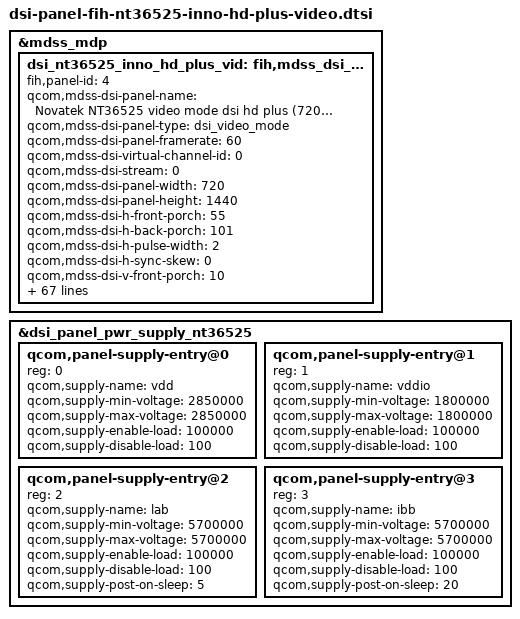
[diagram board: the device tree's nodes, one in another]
/* Copyright (c) 2018, The Linux Foundation. All rights reserved.
 *
 * This program is free software; you can redistribute it and/or modify
 * it under the terms of the GNU General Public License version 2 and
 * only version 2 as published by the Free Software Foundation.
 *
 * This program is distributed in the hope that it will be useful,
 * but WITHOUT ANY WARRANTY; without even the implied warranty of
 * MERCHANTABILITY or FITNESS FOR A PARTICULAR PURPOSE.  See the
 * GNU General Public License for more details.
 */

&mdss_mdp {
	dsi_nt36525_inno_hd_plus_vid: fih,mdss_dsi_nt36525_inno_hd_plus_video{
		fih,panel-id = <4>;
		qcom,mdss-dsi-panel-name = "Novatek NT36525 video mode dsi hd plus (720x1440) inno panel";
		qcom,mdss-dsi-panel-type = "dsi_video_mode";
		qcom,mdss-dsi-panel-framerate = <60>;
		qcom,mdss-dsi-virtual-channel-id = <0>;
		qcom,mdss-dsi-stream = <0>;
		qcom,mdss-dsi-panel-width = <720>;
		qcom,mdss-dsi-panel-height = <1440>;

		qcom,mdss-dsi-h-front-porch = <55>;
		qcom,mdss-dsi-h-back-porch = <101>;
		qcom,mdss-dsi-h-pulse-width = <2>;
		qcom,mdss-dsi-h-sync-skew = <0>;
		qcom,mdss-dsi-v-front-porch = <10>;
		qcom,mdss-dsi-v-back-porch = <8>;
		qcom,mdss-dsi-v-pulse-width = <2>;

		qcom,mdss-dsi-h-left-border = <0>;
		qcom,mdss-dsi-h-right-border = <0>;
		qcom,mdss-dsi-v-top-border = <0>;
		qcom,mdss-dsi-v-bottom-border = <0>;
		qcom,mdss-dsi-bpp = <24>;
		qcom,mdss-dsi-color-order = "rgb_swap_rgb";
		qcom,mdss-dsi-underflow-color = <0xff>;
		qcom,mdss-dsi-border-color = <0>;
		qcom,mdss-dsi-on-command = [
                    39 01 00 00 0A 00 02 FF 20
                    39 01 00 00 00 00 02 FB 01
                    39 01 00 00 00 00 02 01 55
                    39 01 00 00 00 00 02 03 55
                    39 01 00 00 00 00 02 05 B1
                    39 01 00 00 00 00 02 07 73
                    39 01 00 00 00 00 02 08 CB
                    39 01 00 00 00 00 02 0E 91
                    39 01 00 00 00 00 02 0F 69
                    39 01 00 00 00 00 02 69 A9
                    39 01 00 00 00 00 02 94 00
                    39 01 00 00 00 00 02 95 FF
                    39 01 00 00 00 00 02 96 FF
                    39 01 00 00 0A 00 02 FF 24
                    39 01 00 00 00 00 02 FB 01
                    39 01 00 00 00 00 02 93 0A
                    39 01 00 00 00 00 02 94 0A
                    39 01 00 00 00 00 02 00 04
                    39 01 00 00 00 00 02 01 05
                    39 01 00 00 00 00 02 02 00
                    39 01 00 00 00 00 02 03 00
                    39 01 00 00 00 00 02 04 08
                    39 01 00 00 00 00 02 05 18
                    39 01 00 00 00 00 02 06 19
                    39 01 00 00 00 00 02 07 0C
                    39 01 00 00 00 00 02 08 0D
                    39 01 00 00 00 00 02 09 0E
                    39 01 00 00 00 00 02 0A 0F
                    39 01 00 00 00 00 02 0B 10
                    39 01 00 00 00 00 02 0C 11
                    39 01 00 00 00 00 02 16 04
                    39 01 00 00 00 00 02 17 05
                    39 01 00 00 00 00 02 18 00
                    39 01 00 00 00 00 02 19 00
                    39 01 00 00 00 00 02 1A 08
                    39 01 00 00 00 00 02 1B 18
                    39 01 00 00 00 00 02 1C 19
                    39 01 00 00 00 00 02 1D 0C
                    39 01 00 00 00 00 02 1E 0D
                    39 01 00 00 00 00 02 1F 0E
                    39 01 00 00 00 00 02 20 0F
                    39 01 00 00 00 00 02 21 10
                    39 01 00 00 00 00 02 22 11
                    39 01 00 00 00 00 02 2F 04
                    39 01 00 00 00 00 02 30 32
                    39 01 00 00 00 00 02 33 32
                    39 01 00 00 00 00 02 34 04
                    39 01 00 00 00 00 02 37 44
                    39 01 00 00 00 00 02 39 00
                    39 01 00 00 00 00 02 3A 10
                    39 01 00 00 00 00 02 3B A3
                    39 01 00 00 00 00 02 3D 52
                    39 01 00 00 00 00 02 3F 41
                    39 01 00 00 00 00 02 40 00
                    39 01 00 00 00 00 02 43 41
                    39 01 00 00 00 00 02 44 06
                    39 01 00 00 00 00 02 47 44
                    39 01 00 00 00 00 02 49 00
                    39 01 00 00 00 00 02 4A 10
                    39 01 00 00 00 00 02 4B A3
                    39 01 00 00 00 00 02 4C 51
                    39 01 00 00 00 00 02 4D 12
                    39 01 00 00 00 00 02 4E 34
                    39 01 00 00 00 00 02 4F 56
                    39 01 00 00 00 00 02 51 65
                    39 01 00 00 00 00 02 52 43
                    39 01 00 00 00 00 02 53 21
                    39 01 00 00 00 00 02 55 43
                    39 01 00 00 00 00 02 56 46
                    39 01 00 00 00 00 02 5A 10
                    39 01 00 00 00 00 02 5B A3
                    39 01 00 00 00 00 02 5E 06
                    39 01 00 00 00 00 02 5F 00
                    39 01 00 00 00 00 02 92 C0
                    39 01 00 00 00 00 02 76 00
                    39 01 00 00 00 00 02 77 00
                    39 01 00 00 00 00 02 78 00
                    39 01 00 00 00 00 02 79 00
                    39 01 00 00 00 00 02 7A 20
                    39 01 00 00 00 00 02 7B 3C
                    39 01 00 00 00 00 02 7C 00
                    39 01 00 00 00 00 02 7D 00
                    39 01 00 00 00 00 02 7E 08
                    39 01 00 00 00 00 02 87 02
                    39 01 00 00 00 00 02 AB 00
                    39 01 00 00 00 00 02 AC 00
                    39 01 00 00 00 00 02 AD 00
                    39 01 00 00 00 00 02 AF 04
                    39 01 00 00 00 00 02 B0 05
                    39 01 00 00 00 00 02 B1 BB
                    39 01 00 00 00 00 02 60 80
                    39 01 00 00 00 00 02 61 68
                    39 01 00 00 00 00 02 64 11
                    39 01 00 00 0A 00 02 FF 25
                    39 01 00 00 00 00 02 FB 01
                    39 01 00 00 00 00 02 0A 82
                    39 01 00 00 00 00 02 0B BE
                    39 01 00 00 00 00 02 0C 01
                    39 01 00 00 00 00 02 17 82
                    39 01 00 00 00 00 02 18 06
                    39 01 00 00 00 00 02 19 0F
                    39 01 00 00 00 00 02 1E 00
                    39 01 00 00 00 00 02 1F 10
                    39 01 00 00 00 00 02 20 A3
                    39 01 00 00 00 00 02 23 05
                    39 01 00 00 00 00 02 24 BB
                    39 01 00 00 00 00 02 25 00
                    39 01 00 00 00 00 02 26 10
                    39 01 00 00 00 00 02 27 A3
                    39 01 00 00 00 00 02 2A 05
                    39 01 00 00 00 00 02 2B BB
                    39 01 00 00 00 00 02 2D 80
                    39 01 00 00 00 00 02 2F 50
                    39 01 00 00 00 00 02 30 10
                    39 01 00 00 00 00 02 31 00
                    39 01 00 00 00 00 02 32 00
                    39 01 00 00 00 00 02 33 10
                    39 01 00 00 00 00 02 34 A3
                    39 01 00 00 00 00 02 37 05
                    39 01 00 00 00 00 02 38 BB
                    39 01 00 00 00 00 02 40 10
                    39 01 00 00 00 00 02 41 80
                    39 01 00 00 00 00 02 42 10
                    39 01 00 00 00 00 02 43 A3
                    39 01 00 00 00 00 02 46 05
                    39 01 00 00 00 00 02 47 BB
                    39 01 00 00 00 00 02 4A 00
                    39 01 00 00 00 00 02 4B 10
                    39 01 00 00 00 00 02 4C A3
                    39 01 00 00 00 00 02 4D 10
                    39 01 00 00 00 00 02 4E A3
                    39 01 00 00 00 00 02 4F 10
                    39 01 00 00 00 00 02 50 A3
                    39 01 00 00 00 00 02 53 05
                    39 01 00 00 00 00 02 54 BB
                    39 01 00 00 00 00 02 55 05
                    39 01 00 00 00 00 02 56 BB
                    39 01 00 00 00 00 02 58 00
                    39 01 00 00 00 00 02 59 00
                    39 01 00 00 00 00 02 5A 60
                    39 01 00 00 00 00 02 5B 80
                    39 01 00 00 00 00 02 5C 00
                    39 01 00 00 00 00 02 5D 10
                    39 01 00 00 00 00 02 5E A3
                    39 01 00 00 00 00 02 5F 10
                    39 01 00 00 00 00 02 60 A3
                    39 01 00 00 00 00 02 61 10
                    39 01 00 00 00 00 02 62 A3
                    39 01 00 00 00 00 02 65 05
                    39 01 00 00 00 00 02 66 BB
                    39 01 00 00 00 00 02 6B 07
                    39 01 00 00 00 00 02 6C 4A
                    39 01 00 00 00 00 02 6D 94
                    39 01 00 00 00 00 02 6E 0D
                    39 01 00 00 00 00 02 6F 17
                    39 01 00 00 00 00 02 70 54
                    39 01 00 00 00 00 02 71 8A
                    39 01 00 00 00 00 02 72 17
                    39 01 00 00 00 00 02 73 0D
                    39 01 00 00 00 00 02 78 00
                    39 01 00 00 00 00 02 79 05
                    39 01 00 00 00 00 02 7A 00
                    39 01 00 00 00 00 02 7B B0
                    39 01 00 00 00 00 02 7C 00
                    39 01 00 00 00 00 02 7D 05
                    39 01 00 00 00 00 02 7E 00
                    39 01 00 00 00 00 02 7F B0
                    39 01 00 00 0A 00 02 FF 26
                    39 01 00 00 00 00 02 FB 01
                    39 01 00 00 00 00 02 04 4B
                    39 01 00 00 00 00 02 06 01
                    39 01 00 00 00 00 02 0C 0B
                    39 01 00 00 00 00 02 0D 01
                    39 01 00 00 00 00 02 0E 02
                    39 01 00 00 00 00 02 0F 06
                    39 01 00 00 00 00 02 10 07
                    39 01 00 00 00 00 02 12 00
                    39 01 00 00 00 00 02 13 28
                    39 01 00 00 00 00 02 14 80
                    39 01 00 00 00 00 02 16 81
                    39 01 00 00 00 00 02 19 15
                    39 01 00 00 00 00 02 1A 6A
                    39 01 00 00 00 00 02 1B 0D
                    39 01 00 00 00 00 02 1C D2
                    39 01 00 00 00 00 02 1D 00
                    39 01 00 00 00 00 02 1E C0
                    39 01 00 00 00 00 02 1F C0
                    39 01 00 00 00 00 02 24 01
                    39 01 00 00 00 00 02 25 C0
                    39 01 00 00 00 00 02 26 66
                    39 01 00 00 00 00 02 27 66
                    39 01 00 00 00 00 02 28 66
                    39 01 00 00 00 00 02 29 06
                    39 01 00 00 00 00 02 2F 00
                    39 01 00 00 00 00 02 30 C0
                    39 01 00 00 00 00 02 31 11
                    39 01 00 00 00 00 02 32 11
                    39 01 00 00 00 00 02 34 05
                    39 01 00 00 00 00 02 35 C0
                    39 01 00 00 00 00 02 36 11
                    39 01 00 00 00 00 02 37 78
                    39 01 00 00 00 00 02 38 66
                    39 01 00 00 00 00 02 39 06
                    39 01 00 00 00 00 02 3F 06
                    39 01 00 00 00 00 02 40 C0
                    39 01 00 00 00 00 02 41 66
                    39 01 00 00 00 00 02 42 66
                    39 01 00 00 00 00 02 43 06
                    39 01 00 00 00 00 02 58 E1
                    39 01 00 00 00 00 02 59 E1
                    39 01 00 00 00 00 02 5A E1
                    39 01 00 00 00 00 02 5B E1
                    39 01 00 00 00 00 02 5C 00
                    39 01 00 00 00 00 02 5D 00
                    39 01 00 00 00 00 02 5E 06
                    39 01 00 00 00 00 02 5F 66
                    39 01 00 00 00 00 02 60 66
                    39 01 00 00 00 00 02 61 06
                    39 01 00 00 00 00 02 63 10
                    39 01 00 00 00 00 02 64 A3
                    39 01 00 00 00 00 02 65 10
                    39 01 00 00 00 00 02 66 A3
                    39 01 00 00 00 00 02 67 10
                    39 01 00 00 00 00 02 68 A3
                    39 01 00 00 00 00 02 6B 00
                    39 01 00 00 00 00 02 6C 00
                    39 01 00 00 00 00 02 6D 00
                    39 01 00 00 00 00 02 6F 04
                    39 01 00 00 00 00 02 70 05
                    39 01 00 00 00 00 02 71 DC
                    39 01 00 00 00 00 02 73 10
                    39 01 00 00 00 00 02 74 A3
                    39 01 00 00 00 00 02 77 05
                    39 01 00 00 00 00 02 78 DC
                    39 01 00 00 00 00 02 7A 10
                    39 01 00 00 00 00 02 7B A3
                    39 01 00 00 00 00 02 7E 05
                    39 01 00 00 00 00 02 7F DC
                    39 01 00 00 00 00 02 82 10
                    39 01 00 00 00 00 02 83 A3
                    39 01 00 00 00 00 02 84 10
                    39 01 00 00 00 00 02 85 A3
                    39 01 00 00 00 00 02 86 10
                    39 01 00 00 00 00 02 87 A3
                    39 01 00 00 00 00 02 8A 05
                    39 01 00 00 00 00 02 8B DC
                    39 01 00 00 00 00 02 8C 00
                    39 01 00 00 00 00 02 8D 00
                    39 01 00 00 00 00 02 8E 01
                    39 01 00 00 00 00 02 8F 00
                    39 01 00 00 00 00 02 90 00
                    39 01 00 00 00 00 02 91 00
                    39 01 00 00 00 00 02 92 05
                    39 01 00 00 00 00 02 93 A0
                    39 01 00 00 00 00 02 94 00
                    39 01 00 00 00 00 02 95 00
                    39 01 00 00 00 00 02 96 00
                    39 01 00 00 00 00 02 99 18
                    39 01 00 00 00 00 02 9A 06
                    39 01 00 00 00 00 02 9B 17
                    39 01 00 00 00 00 02 9C 6E
                    39 01 00 00 0A 00 02 FF 27
                    39 01 00 00 00 00 02 FB 01
                    39 01 00 00 00 00 02 96 03
                    39 01 00 00 00 00 02 97 15
                    39 01 00 00 00 00 02 98 11
                    39 01 00 00 00 00 02 99 3F
                    39 01 00 00 00 00 02 9B 3F
                    39 01 00 00 00 00 02 9D 25
                    39 01 00 00 00 00 02 9E 55
                    39 01 00 00 00 00 02 9F 05
                    39 01 00 00 00 00 02 AD 25
                    39 01 00 00 00 00 02 AE 55
                    39 01 00 00 00 00 02 AF 05
                    39 01 00 00 00 00 02 B3 C6
                    39 01 00 00 0A 00 02 FF 23
                    39 01 00 00 00 00 02 FB 01
                    39 01 00 00 00 00 02 12 A2
                    39 01 00 00 00 00 02 15 81
                    39 01 00 00 00 00 02 16 0A
			39 01 00 00 0A 00 02 FF 20 
			39 01 00 00 00 00 02 FB 01 
			39 01 00 00 00 00 11 B0 00 00 00 0D 00 26 00 3B 00 4E 00 5F 00 6E 00 7C 
			39 01 00 00 00 00 11 B1 00 8A 00 B7 00 DC 01 16 01 44 01 8D 01 C9 01 CA 
			39 01 00 00 00 00 11 B2 02 01 02 42 02 6C 02 A5 02 CC 02 F8 03 04 03 11 
			39 01 00 00 00 00 0D B3 03 27 03 36 03 44 03 50 03 57 03 DB 
			39 01 00 00 00 00 11 B4 00 00 00 0D 00 26 00 3B 00 4E 00 5F 00 6E 00 7C 
			39 01 00 00 00 00 11 B5 00 8A 00 B7 00 DC 01 16 01 44 01 8D 01 C9 01 CA 
			39 01 00 00 00 00 11 B6 02 01 02 42 02 6C 02 A5 02 CC 02 F8 03 04 03 11 
			39 01 00 00 00 00 0D B7 03 27 03 36 03 44 03 50 03 57 03 DB 
			39 01 00 00 00 00 11 B8 00 00 00 0D 00 26 00 3B 00 4E 00 5F 00 6E 00 7C 
			39 01 00 00 00 00 11 B9 00 8A 00 B7 00 DC 01 16 01 44 01 8D 01 C9 01 CA 
			39 01 00 00 00 00 11 BA 02 01 02 42 02 6C 02 A5 02 CC 02 F8 03 04 03 11 
			39 01 00 00 00 00 0D BB 03 27 03 36 03 44 03 50 03 57 03 DB 
			39 01 00 00 0A 00 02 FF 21 
			39 01 00 00 00 00 02 FB 01 
			39 01 00 00 00 00 11 B0 00 00 00 0D 00 26 00 3B 00 4E 00 5F 00 6E 00 7C 
			39 01 00 00 00 00 11 B1 00 8A 00 B7 00 DC 01 16 01 44 01 8D 01 C9 01 CA 
			39 01 00 00 00 00 11 B2 02 01 02 42 02 6C 02 A5 02 CC 02 F8 03 04 03 11 
			39 01 00 00 00 00 0D B3 03 27 03 36 03 44 03 50 03 57 03 DB 
			39 01 00 00 00 00 11 B4 00 00 00 0D 00 26 00 3B 00 4E 00 5F 00 6E 00 7C 
			39 01 00 00 00 00 11 B5 00 8A 00 B7 00 DC 01 16 01 44 01 8D 01 C9 01 CA 
			39 01 00 00 00 00 11 B6 02 01 02 42 02 6C 02 A5 02 CC 02 F8 03 04 03 11 
			39 01 00 00 00 00 0D B7 03 27 03 36 03 44 03 50 03 57 03 DB 
			39 01 00 00 00 00 11 B8 00 00 00 0D 00 26 00 3B 00 4E 00 5F 00 6E 00 7C 
			39 01 00 00 00 00 11 B9 00 8A 00 B7 00 DC 01 16 01 44 01 8D 01 C9 01 CA 
			39 01 00 00 00 00 11 BA 02 01 02 42 02 6C 02 A5 02 CC 02 F8 03 04 03 11 
			39 01 00 00 00 00 0D BB 03 27 03 36 03 44 03 50 03 57 03 DB 
                    39 01 00 00 0A 00 02 FF 10
                    39 01 00 00 00 00 02 FB 01
                    05 01 00 00 00 00 02 29 00
                    05 01 00 00 78 00 02 11 00
		];
		qcom,mdss-dsi-off-command = [
				05 00 00 00 00 00 02 28 00
				05 01 00 00 96 00 02 10 00
		];
		qcom,mdss-dsi-on-command-state = "dsi_lp_mode";
		qcom,mdss-dsi-off-command-state = "dsi_lp_mode";
		qcom,mdss-dsi-h-sync-pulse = <0>;
		qcom,mdss-dsi-traffic-mode = "non_burst_sync_event";
		qcom,mdss-dsi-lane-map = "lane_map_0123";
		qcom,mdss-dsi-bllp-eof-power-mode;
		qcom,mdss-dsi-bllp-power-mode;
		qcom,mdss-dsi-tx-eot-append;
		qcom,mdss-dsi-lane-0-state;
		qcom,mdss-dsi-lane-1-state;
		qcom,mdss-dsi-lane-2-state;
		qcom,mdss-dsi-lane-3-state;
		qcom,mdss-dsi-t-clk-post = <0x04>;
		qcom,mdss-dsi-t-clk-pre = <0x1B>;
		qcom,mdss-dsi-dma-trigger = "trigger_sw";
		qcom,mdss-dsi-mdp-trigger = "none";
		qcom,mdss-dsi-reset-sequence = <1 20>;

		qcom,mdss-pan-physical-width-dimension = <68>;
		qcom,mdss-pan-physical-height-dimension = <136>;
		qcom,mdss-pan-physical-width-dimension-full = <6804>;
		qcom,mdss-pan-physical-height-dimension-full = <13608>;

		/* ******************** */
		/* START of Dynamic Read Write Register */
		/* ******************** */
		/* SW4-HL-Display-DynamicReadWriteRegister-00+{_20160729 */
		fih,mdss-dsi-write-reg-command = [
			39 01 00 00 00 00 04 FF 78 07 00
		];

		fih,mdss-dsi-write-reg-command-state = "dsi_lp_mode";
		/* SW4-HL-Display-DynamicReadWriteRegister-00+}_20160729 */
		/* ******************** */
		/* START of Dynamic Read Write Register */
		/* ******************** */
	};
};

&dsi_nt36525_inno_hd_plus_vid {
	/delete-property/ qcom,mdss-dsi-panel-timings;
	qcom,mdss-dsi-panel-timings = [
		88 1C 12 00 42 44 18 20 16 03 04 00
	];

	qcom,mdss-dsi-panel-timings-phy-v2 = [
		1E 1C 04 06 02 03 04 a0
		1E 1C 04 06 02 03 04 a0
		1E 1C 04 06 02 03 04 a0
		1E 1C 04 06 02 03 04 a0
		1E 1C 04 06 02 03 04 a0
	];

	qcom,mdss-dsi-panel-timings-phy-12nm = [
		09 06 0a 02 00 05 02 08
	];

	qcom,mdss-dsi-bl-pmic-control-type = "bl_ctrl_pwm";
	qcom,mdss-dsi-bl-pmic-pwm-frequency = <40>;
	qcom,mdss-dsi-bl-pmic-bank-select = <0>;
	qcom,mdss-dsi-pwm-gpio = <&pm8953_gpios 8 0>;

	/* PMI439 Can Not Ouput Signal When Frequency Is Set As 25KHZ And Bl Level is less than 4 */
	qcom,mdss-dsi-bl-min-level = <4>;

	qcom,panel-supply-entries = <&dsi_panel_pwr_supply_nt36525>;
        
	/******************************************/
	/* ESD Check Recovery  - START */
	/******************************************/
	qcom,esd-check-enabled;
	qcom,mdss-dsi-panel-status-check-mode = "reg_read";
	qcom,mdss-dsi-panel-status-command = [
		06 01 00 01 00 00 01 0A
	];
	qcom,mdss-dsi-panel-status-command-state = "dsi_lp_mode";
	qcom,mdss-dsi-panel-status-value = <0x9C>;
	qcom,mdss-dsi-panel-on-check-value = <0x9C>;
	qcom,mdss-dsi-panel-status-read-length = <1>;
	qcom,mdss-dsi-panel-max-error-count = <3>;
	/*****************************************/
	/* ESD Check Recovery  - END     */
	/*****************************************/        
};


&dsi_panel_pwr_supply_nt36525 {
        #address-cells = <1>;
        #size-cells = <0>;

        qcom,panel-supply-entry@0 {
                reg = <0>;
                qcom,supply-name = "vdd";
                qcom,supply-min-voltage = <2850000>;
                qcom,supply-max-voltage = <2850000>;
                qcom,supply-enable-load = <100000>;
                qcom,supply-disable-load = <100>;
        };

        qcom,panel-supply-entry@1 {
                reg = <1>;
                qcom,supply-name = "vddio";
                qcom,supply-min-voltage = <1800000>;
                qcom,supply-max-voltage = <1800000>;
                qcom,supply-enable-load = <100000>;
                qcom,supply-disable-load = <100>;
        };

        qcom,panel-supply-entry@2 {
                reg = <2>;
                qcom,supply-name = "lab";
                qcom,supply-min-voltage = <5700000>;
                qcom,supply-max-voltage = <5700000>;
                qcom,supply-enable-load = <100000>;
                qcom,supply-disable-load = <100>;
                qcom,supply-post-on-sleep = <5>;
        };

        qcom,panel-supply-entry@3 {
                reg = <3>;
                qcom,supply-name = "ibb";
                qcom,supply-min-voltage = <5700000>;
                qcom,supply-max-voltage = <5700000>;
                qcom,supply-enable-load = <100000>;
                qcom,supply-disable-load = <100>;
                qcom,supply-post-on-sleep = <20>;
        };
};
